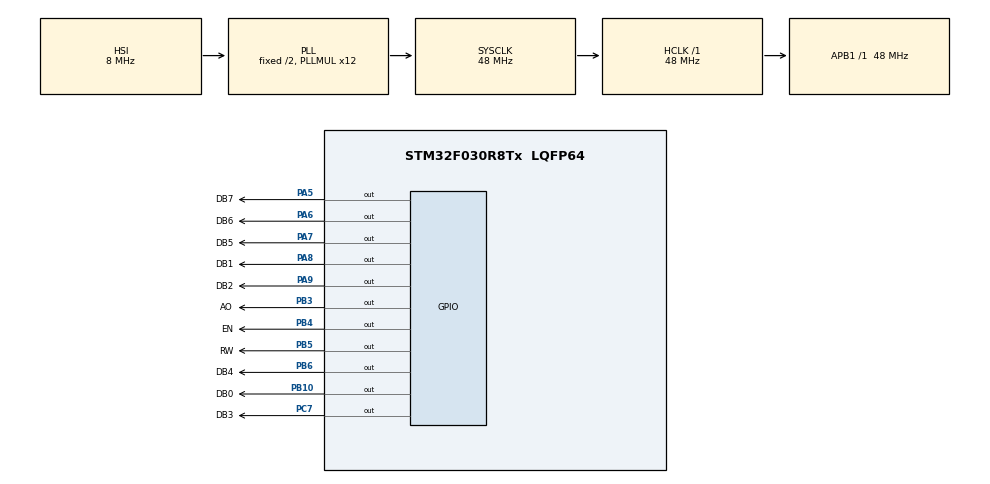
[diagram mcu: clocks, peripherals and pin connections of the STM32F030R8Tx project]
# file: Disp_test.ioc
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Mcu.Family=STM32F0
Mcu.Name=STM32F030R8Tx
Mcu.Package=LQFP64
PA5.GPIO_Label=DB7
PA5.Signal=GPIO_Output
PA6.GPIO_Label=DB6
PA6.Signal=GPIO_Output
PA7.GPIO_Label=DB5
PA7.Signal=GPIO_Output
PA8.GPIO_Label=DB1
PA8.Signal=GPIO_Output
PA9.GPIO_Label=DB2
PA9.Signal=GPIO_Output
PB10.GPIO_Label=DB0
PB10.Signal=GPIO_Output
PB3.GPIO_Label=AO
PB3.Signal=GPIO_Output
PB4.GPIO_Label=EN
PB4.Signal=GPIO_Output
PB5.GPIO_Label=RW
PB5.Signal=GPIO_Output
PB6.GPIO_Label=DB4
PB6.Signal=GPIO_Output
PC7.GPIO_Label=DB3
PC7.Signal=GPIO_Output
ProjectManager.HeapSize=0x200
ProjectManager.StackSize=0x400
ProjectManager.TargetToolchain=STM32CubeIDE
RCC.AHBFreq_Value=48000000
RCC.APB1Freq_Value=48000000
RCC.APB1TimFreq_Value=48000000
RCC.HCLKFreq_Value=48000000
RCC.PLLMUL=RCC_PLL_MUL12
RCC.SYSCLKFreq_VALUE=48000000
RCC.SYSCLKSource=RCC_SYSCLKSOURCE_PLLCLK
board=custom

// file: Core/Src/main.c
/* USER CODE BEGIN Header */
/**
  ******************************************************************************
  * @file           : main.c
  * @brief          : Main program body
  ******************************************************************************
  * @attention
  *
  * Copyright (c) 2023 STMicroelectronics.
  * All rights reserved.
  *
  * This software is licensed under terms that can be found in the LICENSE file
  * in the root directory of this software component.
  * If no LICENSE file comes with this software, it is provided AS-IS.
  *
  ******************************************************************************
  */
/* USER CODE END Header */
#include "main.h"

/* USER CODE BEGIN Includes */
#include "MT-16S2H.h"
/* USER CODE END Includes */

void SystemClock_Config(void);
static void MX_GPIO_Init(void);

int main(void)
{

  /* MCU Configuration--------------------------------------------------------*/

  /* Reset of all peripherals, Initializes the Flash interface and the Systick. */
  HAL_Init();

  /* Configure the system clock */
  SystemClock_Config();

  /* Initialize all configured peripherals */
  MX_GPIO_Init();
  /* USER CODE BEGIN 2 */
  lcdBitMode(BIT8);// Режим работы
  lcdInit();// Инициализация экрана
  lcdWrite("ABOBA");//Выводимый текст
  setCursor(0,1);//Перемещение курсора
  lcdWrite("ОЧЕНЬ БО-БО");

  /* USER CODE END 2 */

  /* Infinite loop */
  while (1)
  {

  }
}

void SystemClock_Config(void)
{
  RCC_OscInitTypeDef RCC_OscInitStruct = {0};
  RCC_ClkInitTypeDef RCC_ClkInitStruct = {0};

  /** Initializes the RCC Oscillators according to the specified parameters
  * in the RCC_OscInitTypeDef structure.
  */
  RCC_OscInitStruct.OscillatorType = RCC_OSCILLATORTYPE_HSI;
  RCC_OscInitStruct.HSIState = RCC_HSI_ON;
  RCC_OscInitStruct.HSICalibrationValue = RCC_HSICALIBRATION_DEFAULT;
  RCC_OscInitStruct.PLL.PLLState = RCC_PLL_ON;
  RCC_OscInitStruct.PLL.PLLSource = RCC_PLLSOURCE_HSI;
  RCC_OscInitStruct.PLL.PLLMUL = RCC_PLL_MUL12;
  RCC_OscInitStruct.PLL.PREDIV = RCC_PREDIV_DIV1;
  if (HAL_RCC_OscConfig(&RCC_OscInitStruct) != HAL_OK)
  {
    Error_Handler();
  }

  /** Initializes the CPU, AHB and APB buses clocks
  */
  RCC_ClkInitStruct.ClockType = RCC_CLOCKTYPE_HCLK|RCC_CLOCKTYPE_SYSCLK
                              |RCC_CLOCKTYPE_PCLK1;
  RCC_ClkInitStruct.SYSCLKSource = RCC_SYSCLKSOURCE_PLLCLK;
  RCC_ClkInitStruct.AHBCLKDivider = RCC_SYSCLK_DIV1;
  RCC_ClkInitStruct.APB1CLKDivider = RCC_HCLK_DIV1;

  if (HAL_RCC_ClockConfig(&RCC_ClkInitStruct, FLASH_LATENCY_1) != HAL_OK)
  {
    Error_Handler();
  }
}

static void MX_GPIO_Init(void)
{
  GPIO_InitTypeDef GPIO_InitStruct = {0};

  /* GPIO Ports Clock Enable */
  __HAL_RCC_GPIOA_CLK_ENABLE();
  __HAL_RCC_GPIOB_CLK_ENABLE();
  __HAL_RCC_GPIOC_CLK_ENABLE();

  /*Configure GPIO pin Output Level */
  HAL_GPIO_WritePin(GPIOA, DB7_Pin|DB6_Pin|DB5_Pin|DB1_Pin
                          |DB2_Pin, GPIO_PIN_RESET);

  /*Configure GPIO pin Output Level */
  HAL_GPIO_WritePin(GPIOB, DB0_Pin|AO_Pin|EN_Pin|RW_Pin
                          |DB4_Pin, GPIO_PIN_RESET);

  /*Configure GPIO pin Output Level */
  HAL_GPIO_WritePin(DB3_GPIO_Port, DB3_Pin, GPIO_PIN_RESET);

  /*Configure GPIO pins : DB7_Pin DB6_Pin DB5_Pin DB1_Pin
                           DB2_Pin */
  GPIO_InitStruct.Pin = DB7_Pin|DB6_Pin|DB5_Pin|DB1_Pin
                          |DB2_Pin;
  GPIO_InitStruct.Mode = GPIO_MODE_OUTPUT_PP;
  GPIO_InitStruct.Pull = GPIO_NOPULL;
  GPIO_InitStruct.Speed = GPIO_SPEED_FREQ_LOW;
  HAL_GPIO_Init(GPIOA, &GPIO_InitStruct);

  /*Configure GPIO pins : DB0_Pin AO_Pin EN_Pin RW_Pin
                           DB4_Pin */
  GPIO_InitStruct.Pin = DB0_Pin|AO_Pin|EN_Pin|RW_Pin
                          |DB4_Pin;
  GPIO_InitStruct.Mode = GPIO_MODE_OUTPUT_PP;
  GPIO_InitStruct.Pull = GPIO_NOPULL;
  GPIO_InitStruct.Speed = GPIO_SPEED_FREQ_LOW;
  HAL_GPIO_Init(GPIOB, &GPIO_InitStruct);

  /*Configure GPIO pin : DB3_Pin */
  GPIO_InitStruct.Pin = DB3_Pin;
  GPIO_InitStruct.Mode = GPIO_MODE_OUTPUT_PP;
  GPIO_InitStruct.Pull = GPIO_NOPULL;
  GPIO_InitStruct.Speed = GPIO_SPEED_FREQ_LOW;
  HAL_GPIO_Init(DB3_GPIO_Port, &GPIO_InitStruct);

}

void Error_Handler(void)
{
  __disable_irq();
  while (1)
  {
  }
}
